# SIMCOP_L3_MAIN register map
Vendor: Texas Instruments
Peripheral module from a debugger description file (folder omap5430_ES2_PUBLIC).
Registers are 32-bit, access not given, reset 0x0 unless marked. A register's access mark holds for its fields unless they carry their own. Offsets are as the file gives them; lines under a group give offsets from that group; [hi:lo] are bit positions; {n}, {i} and the like mark numbered series; 'fields as' and 'values as' point back to an identical list; <NAME> marks a mode.

## SIMCOP_L3_MAIN
0x00 SIMCOP_HL_REVISION ro reset not defined — MODULE REVISION This register contains the IP revision code in binary coded digital. For example, we have: 0x01 = revision 0.1 and 0x21 = revision 2.1
  [31:0] REV — Revision ID
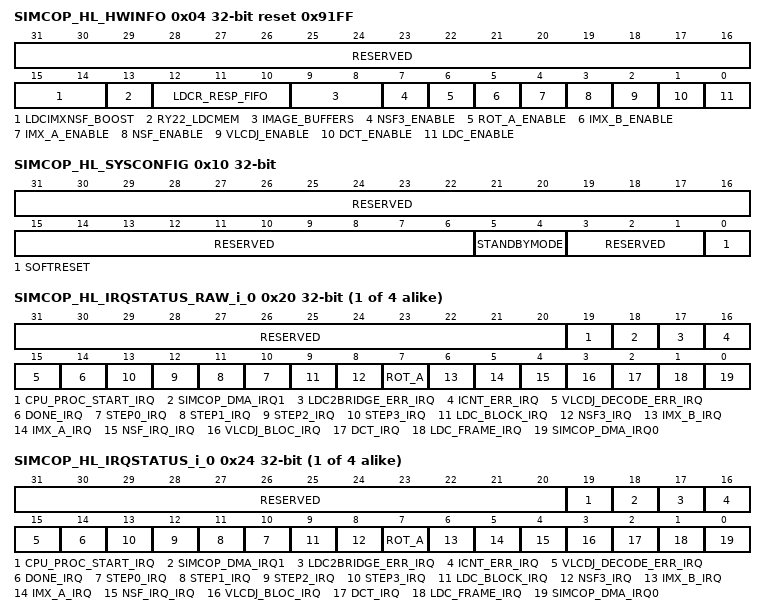
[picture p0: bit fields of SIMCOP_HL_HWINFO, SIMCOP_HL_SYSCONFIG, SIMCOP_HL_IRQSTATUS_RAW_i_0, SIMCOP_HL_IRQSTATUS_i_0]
0x04 SIMCOP_HL_HWINFO ro reset 0x91FF — Information about the IP module's hardware configuration. It provides information about the generic parameters.
  [31:16] RESERVED — Read returns 0.
  [15:14] LDCIMXNSF_BOOST — Read 0x2: SIMCOP receives a main clock at 304 MHz plus a clock at 426 MHz for NSF and iMX
    1=SIMCOP_1 (SIMCOP receives a 400-Mhz clock. Some modules receive the 400-MHz clock and others receive 200MHz.); 0=SIMCOP_receives_200-MHz_clock
  [13] RY22_LDCMEM — Chooses the LDC working memory configuration
    1=YUV4:2:0_1 (Working memory only populated for YUV4:2:0 operation); 0=YUV4:2:2_0 (Working memory fully populated. Supports YUV4:2:2 operation)
  [12:10] LDCR_RESP_FIFO — Defines the size of the LDC read master response FIFO in words of 128-bits.
    2=8x128_bits; 3=16x128_bits; 4=32x128_bits; 5=64x128_bits; 6=128x128_bits; 7=256x256_bits
  [9:8] IMAGE_BUFFERS — This parameter defines the image buffer count.
    0=4_Image_buffers_(e,_f,_g,_and_h); 1=8_Image_buffers
  [7] NSF3_ENABLE — The NSF3 module is present when this parameter is set
    0=Disabled_at_design_time; 1=Enabled_at_design_time
  [6] ROT_A_ENABLE — The ROT A module is present when this parameter is set.
    0=Disabled_at_design_time; 1=Enabled_at_design_time
  [5] IMX_B_ENABLE — The IMX B module and the CMD b, COEFF b memories are present when this parameter is set.
    0=Disabled_at_design_time; 1=Enabled_at_design_time
  [4] IMX_A_ENABLE — The IMX A module and the CMD a, COEFF a memories are present when this parameter is set.
    0=Disabled_at_design_time; 1=Enabled_at_design_time
  [3] NSF_ENABLE — The NSF2 module is present when this parameter is set.
    0=Disabled_at_design_time; 1=Enabled_at_design_time
  [2] VLCDJ_ENABLE — The VLCD module and the QUANT, HUFFMAN, BITSTREAM memories are present when this parameter is set.
    0=Disabled_at_design_time; 1=Enabled_at_design_time
  [1] DCT_ENABLE — The DCT module is present when this parameter is set.
    0=Disabled_at_design_time; 1=Enabled_at_design_time
  [0] LDC_ENABLE — The LDC module and the LDC LUT are present when this parameter is set.
    0=Disabled_at_design_time; 1=Enabled_at_design_time
0x10 SIMCOP_HL_SYSCONFIG access per field — This register controls the various parameters of the OCP interface
  [31:6] RESERVED ro — Read returns 0.
  [5:4] STANDBYMODE rw — Configuration of the local initiator state management mode. By definition, initiator may generate read/write transaction as long as it is out of STANDBY state.
    0=Force-standby mode: local initiator is unconditionally placed in standby state. Backup mode, for debug only.; 1=No-standby mode: local initiator is unconditionally placed out of standby state. Backup mode, for debug only.; 2=Smart-standby mode: local initiator standby status depends on local conditions, i.e. the module's functional requirement from the initiator.
  [3:1] RESERVED ro — Read returns 0.
  [0] SOFTRESET rw — Software reset
    0=Reset_done,_no_pending_action; 0=No_action; 1=Initiate_software_reset; 1=Reset_(software_or_other)_ongoing
{0x20+0x10*i} SIMCOP_HL_IRQSTATUS_RAW_i_{i} (i=0..3) — Per-event raw interrupt status vector Raw status is set even if event is not enabled. Write 1 to set the (raw) status, mostly for debug.
  [31:20] RESERVED ro — Read returns 0.
  [19] CPU_PROC_START_IRQ — Event triggered by the HW sequencer to instruct the CPU to process a macroblock (access RW W1toSet)
    0=No_action; 0=No_event_pending; 1=Event_pending; 1=Set_event_(debug)
  [18] SIMCOP_DMA_IRQ1 ro — Event triggered by the SIMCOP DMA. This event is automatically cleared at SIMCOP level when it is cleared at SIMCOP DMA level Check SIMCOP DMA IRQ registers.
    0=No_event_pending; 1=Event_pending
  [17] LDC2BRIDGE_ERR_IRQ — The LDC2 bridge has generated an error. (access RW W1toSet)
    values as CPU_PROC_START_IRQ
  [16] ICNT_ERR_IRQ — An error has been received on the SIMCOP master port. (access RW W1toSet)
    values as CPU_PROC_START_IRQ
  [15] VLCDJ_DECODE_ERR_IRQ — A decode error has been signaled by the VLCDJ module (access RW W1toSet)
    values as CPU_PROC_START_IRQ
  [14] DONE_IRQ — Event triggered when the HW sequencer finishes the sequence: - the sequence step counter has reached the limit - all accelerator and DMA events for the last sequence step have been received. (access RW W1toSet)
    values as CPU_PROC_START_IRQ
  [n+10] STEP{n}_IRQ (n=0..3) — Event triggered when STEP{n} is activated by the HW sequencer (access RW W1toSet)
    values as CPU_PROC_START_IRQ
  [9] LDC_BLOCK_IRQ — This event is triggered by LDC when a macroblock has been processed (access RW W1toSet)
    values as CPU_PROC_START_IRQ
  [8] NSF3_IRQ — Event triggered by NSF3 imaging accelerator when processing of a block is done (access RW W1toSet)
    values as CPU_PROC_START_IRQ
  [7] ROT_A — Event triggered by the ROT A engine (access RW W1toSet)
    values as CPU_PROC_START_IRQ
  [6] IMX_B_IRQ — Event triggered when IMX has executed a SLEEP instruction. (access RW W1toSet)
    values as CPU_PROC_START_IRQ
  [5] IMX_A_IRQ — Event triggered when IMX has executed a SLEEP instruction. (access RW W1toSet)
    values as CPU_PROC_START_IRQ
  [4] NSF_IRQ_IRQ — Event triggered by the NSF2 imaging accelerator when processing of a block is done. (access RW W1toSet)
    values as CPU_PROC_START_IRQ
  [3] VLCDJ_BLOC_IRQ — This event is triggered by VLCDJ when a macro-bloc has been processed (encode/decode) (access RW W1toSet)
    values as CPU_PROC_START_IRQ
  [2] DCT_IRQ — Event triggered when a block has been processed by the DCT module and the filter outcome has been stored to an image buffer. (access RW W1toSet)
    values as CPU_PROC_START_IRQ
  [1] LDC_FRAME_IRQ — This event is triggered by LDC when a full frame has been processed (access RW W1toSet)
    values as CPU_PROC_START_IRQ
  [0] SIMCOP_DMA_IRQ0 ro — Event triggered by the SIMCOP DMA. This event is automatically cleared at SIMCOP level when it is cleared at SIMCOP DMA level Check SIMCOP DMA IRQ registers.
    0=No_event_pending; 1=Event_pending
{0x24+0x10*i} SIMCOP_HL_IRQSTATUS_i_{i} (i=0..3) — Per-event 'enabled' interrupt status vector Enabled status isn't set unless event is enabled. Write 1 to clear the status after interrupt has been serviced (raw status gets cleared, i.e. even if not enabled).
  [31:20] RESERVED ro — Read returns 0.
  [19] CPU_PROC_START_IRQ — Event triggered by the HW sequencer to instruct the CPU to process a macroblock (access RW W1toClr)
    0=No_action; 0=No_(enabled)_event_pending; 1=Event_pending; 1=Clear_(raw)_event
  [18] SIMCOP_DMA_IRQ1 ro — Event triggered by the SIMCOP DMA. This event is automatically cleared at SIMCOP level when it is cleared at SIMCOP DMA level Check SIMCOP DMA IRQ registers.
    0=No_(enabled)_event_pending; 1=Event_pending
  [17] LDC2BRIDGE_ERR_IRQ — The LDC2 bridge has generated an error. (access RW W1toClr)
    values as CPU_PROC_START_IRQ
  [16] ICNT_ERR_IRQ — An error has been received on the SIMCOP master port. (access RW W1toClr)
    values as CPU_PROC_START_IRQ
  [15] VLCDJ_DECODE_ERR_IRQ — A decode error has been signaled by the VLCDJ module (access RW W1toClr)
    values as CPU_PROC_START_IRQ
  [14] DONE_IRQ — Event triggered when the HW sequencer finishes the sequence: - the sequence step counter has reached the limit - all accelerator and DMA events for the last sequence step have been received. (access RW W1toClr)
    values as CPU_PROC_START_IRQ
  [n+10] STEP{n}_IRQ (n=0..3) — Event triggered when STEP{n} is activated by the HW sequencer (access RW W1toClr)
    values as CPU_PROC_START_IRQ
  [9] LDC_BLOCK_IRQ — This event is triggered by LDC when a macroblock has been processed (access RW W1toClr)
    values as CPU_PROC_START_IRQ
  [8] NSF3_IRQ — Event triggered by the NSF3 imaging accelerator when processing of a block is done (access RW W1toClr)
    values as CPU_PROC_START_IRQ
  [7] ROT_A — Event triggered by the ROT A engine (access RW W1toClr)
    values as CPU_PROC_START_IRQ
  [6] IMX_B_IRQ — Event triggered when IMX has executed a SLEEP instruction. (access RW W1toClr)
    values as CPU_PROC_START_IRQ
  [5] IMX_A_IRQ — Event triggered when IMX has executed a SLEEP instruction. (access RW W1toClr)
    values as CPU_PROC_START_IRQ
  [4] NSF_IRQ_IRQ — Event triggered by the NSF2 imaging accelerator when processing of a block is done. (access RW W1toClr)
    values as CPU_PROC_START_IRQ
  [3] VLCDJ_BLOC_IRQ — This event is triggered by VLCDJ when a macro-bloc has been processed (encode/decode) (access RW W1toClr)
    values as CPU_PROC_START_IRQ
  [2] DCT_IRQ — Event triggered when a block has been processed by the DCT module and the filter outcome has been stored to an image buffer. (access RW W1toClr)
    values as CPU_PROC_START_IRQ
  [1] LDC_FRAME_IRQ — This event is triggered by LDC when a full frame has been processed (access RW W1toClr)
    values as CPU_PROC_START_IRQ
  [0] SIMCOP_DMA_IRQ0 ro — Event triggered by the SIMCOP DMA. This event is automatically cleared at SIMCOP level when it is cleared at SIMCOP DMA level Check SIMCOP DMA IRQ registers.
    0=No_(enabled)_event_pending; 1=Event_pending
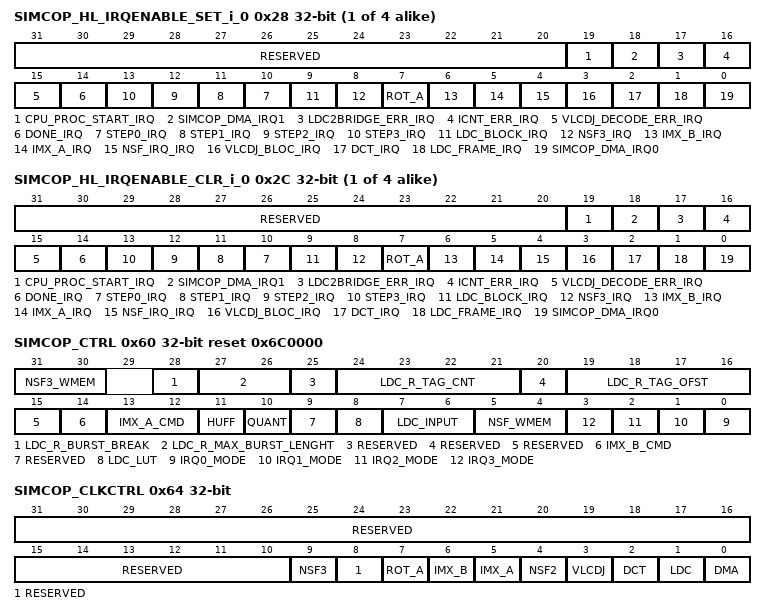
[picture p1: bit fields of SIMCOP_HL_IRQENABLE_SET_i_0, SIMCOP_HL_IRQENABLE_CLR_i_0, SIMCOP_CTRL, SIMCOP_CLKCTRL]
{0x28+0x10*i} SIMCOP_HL_IRQENABLE_SET_i_{i} (i=0..3) — Per-event interrupt enable bit vector Write 1 to set (enable interrupt). Readout equal to corresponding _CLR register.
  [31:20] RESERVED ro — Read returns 0.
  [19] CPU_PROC_START_IRQ — Event triggered by the HW sequencer to instruct the CPU to process a macroblock (access RW W1toSet)
    0=No_action; 0=Interrupt_disabled_(masked); 1=Interrupt_enabled; 1=Enable_interrupt
  [18] SIMCOP_DMA_IRQ1 — Event triggered by the SIMCOP DMA. Check SIMCOP DMA IRQ registers. (access RW W1toSet)
    values as CPU_PROC_START_IRQ
  [17] LDC2BRIDGE_ERR_IRQ — The LDC2 bridge has generated an error. (access RW W1toSet)
    values as CPU_PROC_START_IRQ
  [16] ICNT_ERR_IRQ — An error has been received on the SIMCOP master port. (access RW W1toSet)
    values as CPU_PROC_START_IRQ
  [15] VLCDJ_DECODE_ERR_IRQ — A decode error has been signaled by the VLCDJ module (access RW W1toSet)
    values as CPU_PROC_START_IRQ
  [14] DONE_IRQ — Event triggered when the HW sequencer finishes the sequence: - the sequence step counter has reached the limit - all accelerator and DMA events for the last sequence step have been received. (access RW W1toSet)
    values as CPU_PROC_START_IRQ
  [n+10] STEP{n}_IRQ (n=0..3) — Event triggered when STEP{n} is activated by the HW sequencer (access RW W1toSet)
    values as CPU_PROC_START_IRQ
  [9] LDC_BLOCK_IRQ — This event is triggered by LDC when a macroblock has been processed (access RW W1toSet)
    values as CPU_PROC_START_IRQ
  [8] NSF3_IRQ — Event triggered by the NSF3 imaging accelerator when processing of a block is done (access RW W1toSet)
    values as CPU_PROC_START_IRQ
  [7] ROT_A — Event triggered by the ROT A engine (access RW W1toSet)
    values as CPU_PROC_START_IRQ
  [6] IMX_B_IRQ — Event triggered when IMX has executed a SLEEP instruction. (access RW W1toSet)
    values as CPU_PROC_START_IRQ
  [5] IMX_A_IRQ — Event triggered when IMX has executed a SLEEP instruction. (access RW W1toSet)
    values as CPU_PROC_START_IRQ
  [4] NSF_IRQ_IRQ — Event triggered by the NSF2 imaging accelerator when processing of a block is done. (access RW W1toSet)
    values as CPU_PROC_START_IRQ
  [3] VLCDJ_BLOC_IRQ — This event is triggered by VLCDJ when a macro-bloc has been processed (encode/decode) (access RW W1toSet)
    values as CPU_PROC_START_IRQ
  [2] DCT_IRQ — Event triggered when a block has been processed by the DCT module and the filter outcome has been stored to an image buffer. (access RW W1toSet)
    values as CPU_PROC_START_IRQ
  [1] LDC_FRAME_IRQ — This event is triggered by LDC when a full frame has been processed (access RW W1toSet)
    values as CPU_PROC_START_IRQ
  [0] SIMCOP_DMA_IRQ0 — Event triggered by the SIMCOP DMA. Check SIMCOP DMA IRQ registers. (access RW W1toSet)
    values as CPU_PROC_START_IRQ
{0x2C+0x10*i} SIMCOP_HL_IRQENABLE_CLR_i_{i} (i=0..3) — Per-event interrupt enable bit vector Write 1 to clear (disable interrupt). Readout equal to corresponding _SET register.
  [31:20] RESERVED ro — Read returns 0.
  [19] CPU_PROC_START_IRQ — Event triggered by the HW sequencer to instruct the CPU to process a macroblock (access RW W1toClr)
    0=No_action; 0=Interrupt_disabled_(masked); 1=Interrupt_enabled; 1=Disable_interrupt
  [18] SIMCOP_DMA_IRQ1 — Event triggered by the SIMCOP DMA. Check SIMCOP DMA IRQ registers. (access RW W1toClr)
    values as CPU_PROC_START_IRQ
  [17] LDC2BRIDGE_ERR_IRQ — The LDC2 bridge has generated an error. (access RW W1toClr)
    values as CPU_PROC_START_IRQ
  [16] ICNT_ERR_IRQ — An error has been received on the SIMCOP master port. (access RW W1toClr)
    values as CPU_PROC_START_IRQ
  [15] VLCDJ_DECODE_ERR_IRQ — A decode error has been signaled by the VLCDJ module (access RW W1toClr)
    values as CPU_PROC_START_IRQ
  [14] DONE_IRQ — Event triggered when the HW sequencer finishes the sequence: - the sequence step counter has reached the limit - all accelerator and DMA events for the last sequence step have been received. (access RW W1toClr)
    values as CPU_PROC_START_IRQ
  [n+10] STEP{n}_IRQ (n=0..3) — Event triggered when STEP{n} is activated by the HW sequencer (access RW W1toClr)
    values as CPU_PROC_START_IRQ
  [9] LDC_BLOCK_IRQ — This event is triggered by LDC when a macroblock has been processed (access RW W1toClr)
    values as CPU_PROC_START_IRQ
  [8] NSF3_IRQ — Event triggered by the NSF3 imaging accelerator when processing of a block is done (access RW W1toClr)
    values as CPU_PROC_START_IRQ
  [7] ROT_A — Event triggered by the ROT A engine (access RW W1toClr)
    values as CPU_PROC_START_IRQ
  [6] IMX_B_IRQ — Event triggered when IMX has executed a SLEEP instruction. (access RW W1toClr)
    values as CPU_PROC_START_IRQ
  [5] IMX_A_IRQ — Event triggered when IMX has executed a SLEEP instruction. (access RW W1toClr)
    values as CPU_PROC_START_IRQ
  [4] NSF_IRQ_IRQ — Event triggered by the NSF2 imaging accelerator when processing of a block is done. (access RW W1toClr)
    values as CPU_PROC_START_IRQ
  [3] VLCDJ_BLOC_IRQ — This event is triggered by VLCDJ when a macro-bloc has been processed (encode/decode) (access RW W1toClr)
    values as CPU_PROC_START_IRQ
  [2] DCT_IRQ — Event triggered when a block has been processed by the DCT module and the filter outcome has been stored to an image buffer. (access RW W1toClr)
    values as CPU_PROC_START_IRQ
  [1] LDC_FRAME_IRQ — This event is triggered by LDC when a full frame has been processed (access RW W1toClr)
    values as CPU_PROC_START_IRQ
  [0] SIMCOP_DMA_IRQ0 — Event triggered by the SIMCOP DMA. Check SIMCOP DMA IRQ registers. (access RW W1toClr)
    values as CPU_PROC_START_IRQ
0x60 SIMCOP_CTRL access per field reset 0x6C0000 — SIMCOP control register
  [31:30] NSF3_WMEM rw — Selects working memory for NSF3. Memories attached to NSF3 as working memories cannot be used by any other accelerators. HWSEQ or HWSEQ SW override settings are ignored for those memories.
    0=NSF3._NSF3_0 (No working memory attached to NSF3. NSF3 cannot be used.); 1=IMX_A_+_B_coefficient_memories_used; 2=Image buffers a, b, c, and d used. Those image buffers cannot be used for other purposes. This setting has higher priority than the context configuration
  [28] LDC_R_BURST_BREAK rw — Controls if bursts issued by the LDC2 bridge could cross burst length boundaries. When this register is set, the LDC2 bridge only issues aligned bursts. Register can only be used when LDC_R_MAX_BURST_LENGHT is 32, 64 or 128 bytes.
    0=Yes; 1=No._OCP_transactions_must_be_split
  [27:26] LDC_R_MAX_BURST_LENGHT rw — Limits the maximum burst length that could be used by the LDC2 bridge
    0=8x128; 1=6x128; 2=4x128; 3=2x128
  [25] RESERVED ro — Read returns 0.
  [24:21] LDC_R_TAG_CNT rw — Limits the maximum number of outstanding requests to LDC_R_TAG_CNT+1
  [20] RESERVED ro — Read returns 0.
  [19:16] LDC_R_TAG_OFST rw — First OCP tag ID that can be used by LDC reads. It is SW's responsibility to prevent overlap with tags generated by the SIMCOP DMA Typically this value should be equal to SIMCP_DMA_CTRL.TAG_CNT+1
  [15] RESERVED ro — Read returns 0.
  [14] IMX_B_CMD rw — Switch for IMX # command memory
    0=Coprocessor_bus; 1=IMX_B_instruction_read_/_write
  [13:12] IMX_A_CMD rw — Switch for IMX A command memory
    0=Coprocessor_bus; 1=IMX_A_instruction_read_/_write; 2=IMX_B_instruction_read_/_write
  [11] HUFF rw — Switch for Huffman table
    0=Coprocessor; 1=VLCDJ_Huffman_table_read
  [10] QUANT rw — Switch for quantization table
    0=Coprocessor_bus; 1=VLCDJ_quantization_table_read
  [9] RESERVED ro — Read returns 0.
  [8] LDC_LUT rw — Switch for LDC LUT
    0=Coprocessor_bus; 1=LDC_LDC_LUT._1 (The LDC module could access the LDC LUT.)
  [7:6] LDC_INPUT rw — Selects input data buffer for LDC. Memories attached to LDC as working memories cannot be used by any other accelerators. HWSEQ or HWSEQ SW override settings are ignored for those memories.
    0=No_input_memory_attached; 1=use_image_buffers_a_and_b; 2=use_image_buffers_a,_b,_c,_and_d; 3=Use_LDC_private_input_memory
  [5:4] NSF_WMEM rw — Selects working memory for NSF. Memories attached to NSF as working memories cannot be used by any other accelerators. HWSEQ or HWSEQ SW override settings are ignored for those memories.
    0=NSF2._NSF2_0 (No working memory attached to NSF2. NSF2 cannot be used.); 1=IMX_A_coefficient_memory_used; 2=Image buffers a and b used. Those image buffers cannot be used for other purposes. This setting has higher priority than the context configuration; 3=Image buffers a, b, c, d used. Those image buffers cannot be used for other purposes. This setting has higher priority than the context configuration
  [n] IRQ{n}_MODE rw (n=0..3) — Interrupt generation method
    0=SIMCOP_IRQENABLE_{n}_0 (The interrupt line is asserted when one of the events enabled in SIMCOP_IRQENABLE_{n} is pending); 1=SIMCOP_IRQENABLE_{n}_1 (The interrupt line is asserted when all events enabled in SIMCOP_IRQENABLE_{n} are pending)
0x64 SIMCOP_CLKCTRL — SIMCOP clock control register. Use to enable/disable the interface and functional clock of SIMCOP submodules. Disabled modules cannot be accessed
  [31:10] RESERVED ro — Read returns 0.
  [9] NSF3 rw
    0=NSF3_0_w (Request shutdown of the sub-module. No effect if the sub-module clock is already off); 0=The_sub-module_is_off; 1=The_sub-module_is_on; 1=NSF3_1_w (Request enable of the sub-module. No effect if the sub-module clock is already on)
  [8] RESERVED — Read returns 0.
  [7] ROT_A rw
    0=ROT_A_0_w (Request shutdown of the submodule. No effect if the submodule clock is already off.); 0=The_submodule_is_off; 1=The_submodule_is_on; 1=ROT_A_1_w (Request enable of the submodule. No effect if the submodule clock is already on.)
  [6] IMX_B rw
    0=IMX_B_0_w (Request shutdown of the submodule. No effect if the submodule clock is already off.); 0=The_submodule_is_off; 1=The_submodule_is_on; 1=IMX_B_1_w (Request enable of the submodule. No effect if the submodule clock is already on.)
  [5] IMX_A rw
    0=IMX_A_0_w (Request shutdown of the submodule. No effect if the submodule clock is already off.); 0=The_submodule_is_off; 1=The_submodule_is_on; 1=IMX_A_1_w (Request enable of the submodule. No effect if the submodule clock is already on.)
  [4] NSF2 rw
    0=NSF2_0_w (Request shutdown of the submodule. No effect if the submodule clock is already off.); 0=The_submodule_is_off; 1=The_submodule_is_on; 1=NSF2_1_w (Request enable of the submodule. No effect if the submodule clock is already on.)
  [3] VLCDJ rw
    0=VLCDJ_0_w (Request shutdown of the submodule. No effect if the submodule clock is already off.); 0=The_submodule_is_off; 1=The_submodule_is_on; 1=VLCDJ_1_w (Request enable of the submodule. No effect if the submodule clock is already on.)
  [2] DCT rw
    0=DCT_0_w (Request shutdown of the submodule. No effect if the submodule clock is already off.); 0=The_submodule_is_off; 1=The_submodule_is_on; 1=DCT_1_w (Request enable of the submodule. No effect if the submodule clock is already on.)
  [1] LDC rw
    0=LDC_0_w (Request shutdown of the submodule. No effect if the submodule clock is already off.); 0=The_submodule_is_off; 1=The_submodule_is_on; 1=LDC_1_w (Request enable of the submodule. No effect if the submodule clock is already on.)
  [0] DMA rw
    0=DMA_0_w (Request shutdown of the submodule. No effect if the submodule clock is already off.); 0=The_submodule_is_off; 1=The_submodule_is_on; 1=DMA_1_w (Request enable of the submodule. No effect if the submodule clock is already on.)
0xFC SIMCOP_CTRL2 — Simcop control register
  [11:0] LDCR_BW_CTRL rw — Limits the mean bandwidth (computed over 16 requests) that the LDC module can request for read from system memory1..47: reserved . 48..4095: LDCR_BW_CTRL/4 functional clock cycles between two consecutive requests of 32 bytes. .
    0=The_BW_limiter_is_bypassed
